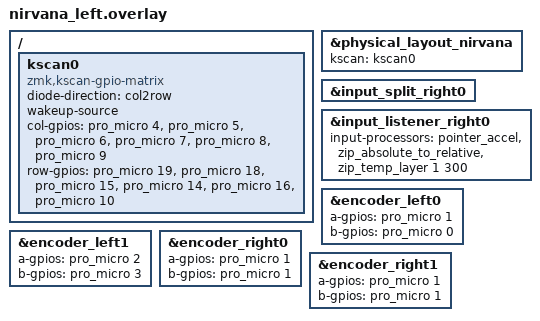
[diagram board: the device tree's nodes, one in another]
#include "nirvana.dtsi"
#include <dt-bindings/zmk/input_transform.h>
#include <input/processors.dtsi>
#include <zephyr/dt-bindings/input/input-event-codes.h>
#include <behaviors/input_processor_gestures.dtsi>

#include <behaviors/input_gestures_accel.dtsi>

/ {
    kscan0: kscan0 {
        compatible = "zmk,kscan-gpio-matrix";
        diode-direction = "col2row";
        wakeup-source;

        col-gpios
            = <&pro_micro 4 GPIO_ACTIVE_HIGH>
            , <&pro_micro 5 GPIO_ACTIVE_HIGH>
            , <&pro_micro 6 GPIO_ACTIVE_HIGH>
            , <&pro_micro 7 GPIO_ACTIVE_HIGH>
            , <&pro_micro 8 GPIO_ACTIVE_HIGH>
            , <&pro_micro 9 GPIO_ACTIVE_HIGH>
            ;

        row-gpios
            = <&pro_micro 19 (GPIO_ACTIVE_HIGH | GPIO_PULL_DOWN)>
            , <&pro_micro 18 (GPIO_ACTIVE_HIGH | GPIO_PULL_DOWN)>
            , <&pro_micro 15 (GPIO_ACTIVE_HIGH | GPIO_PULL_DOWN)>
            , <&pro_micro 14 (GPIO_ACTIVE_HIGH | GPIO_PULL_DOWN)>
            , <&pro_micro 16 (GPIO_ACTIVE_HIGH | GPIO_PULL_DOWN)>
            , <&pro_micro 10 (GPIO_ACTIVE_HIGH | GPIO_PULL_DOWN)>
            ;
    };
};

&physical_layout_nirvana {
    kscan = <&kscan0>;
};
// == Input devices ==
// Input devices on peripheral parts
// Enabling input listeners and input-split to receive input events from peripherals

&input_split_right0 { 
    status = "okay"; 
};

&input_listener_right0 { 
    status = "okay"; 
    input-processors = <
        &pointer_accel 
        //&zip_gestures
        &zip_absolute_to_relative
        //&zip_xy_scaler 3 2
        &zip_temp_layer 1 300
    >;
};

&encoder_left0 {
    a-gpios = <&pro_micro 1 (GPIO_ACTIVE_HIGH | GPIO_PULL_UP)>;
    b-gpios = <&pro_micro 0 (GPIO_ACTIVE_HIGH | GPIO_PULL_UP)>;
    status = "okay";
};
&encoder_left1 {
    a-gpios = <&pro_micro 2 (GPIO_ACTIVE_HIGH | GPIO_PULL_UP)>;
    b-gpios = <&pro_micro 3 (GPIO_ACTIVE_HIGH | GPIO_PULL_UP)>;
    status = "okay";
};

// Assigning dummy pins to other part's encoders
// just to satisfy the devicetree requirements.
// No code will be compiled for these disabled encoders.
&encoder_right0 {
    a-gpios = <&pro_micro 1 (GPIO_ACTIVE_HIGH | GPIO_PULL_UP)>;
    b-gpios = <&pro_micro 1 (GPIO_ACTIVE_HIGH | GPIO_PULL_UP)>;
};
&encoder_right1 {
    a-gpios = <&pro_micro 1 (GPIO_ACTIVE_HIGH | GPIO_PULL_UP)>;
    b-gpios = <&pro_micro 1 (GPIO_ACTIVE_HIGH | GPIO_PULL_UP)>;
};

